# SiFive_FE200 register map
File version: 0.1
From SiFive,FE200,model device generator
Registers are 8-bit, read-write, no defined reset value unless marked. A register's access mark holds for its fields unless they carry their own. Offsets are from the block's base; lines under a group give offsets from that group; [hi:lo] are bit positions; {n}, {i} and the like mark numbered series; 'fields as' and 'values as' point back to an identical list; <NAME> marks a mode.

## Memory map
0x00004000 sifive_test0_0 size 0x1000 — From sifive,test0,control peripheral generator
0x02000000 sifive_clic0_0 size 0x1000000 — From sifive,clic0,control peripheral generator
0x20000000 sifive_uart0_0 size 0x1000 — From sifive,uart0,control peripheral generator
0x20002000 sifive_gpio0_0 size 0x1000 — From sifive,gpio0,control peripheral generator
0x20004000 sifive_spi0_0 size 0x1000 — From sifive,spi0,control peripheral generator
0x20005000 sifive_pwm0_0 size 0x1000 — From sifive,pwm0,control peripheral generator

## sifive_gpio0_0 — From sifive,gpio0,control peripheral generator
Base 0x20002000
0x00 input_val 32-bit — Pin value
0x04 input_en 32-bit — Pin input enable
0x08 output_en 32-bit — Pin output enable
0x0C output_val 32-bit — Output value
0x10 pue 32-bit — Internal pull-up enable
0x14 ds 32-bit — Pin drive strength
0x18 rise_ie 32-bit — Rise interrupt enable
0x1C rise_ip 32-bit — Rise interrupt pending
0x20 fall_ie 32-bit — Fall interrupt enable
0x24 fall_ip 32-bit — Fall interrupt pending
0x28 high_ie 32-bit — High interrupt enable
0x2C high_ip 32-bit — High interrupt pending
0x30 low_ie 32-bit — Low interrupt enable
0x34 low_ip 32-bit — Low interrupt pending
0x38 iof_en 32-bit — I/O function enable
0x3C iof_sel 32-bit — I/O function select
0x40 out_xor 32-bit — Output XOR (invert)

## sifive_clic0_0 — From sifive,clic0,control peripheral generator
Base 0x02000000
0x00 msip_0 32-bit — MSIP Register for hart 0
0x4000 mtimecmp_0 64-bit — MTIMECMP Register for hart 0
0xBFF8 mtime 64-bit
{0x800000+i} clicintip_{i} (i=0..172) — CLICINTIP Register for interrupt id {i}
{0x800400+i} clicintie_{i} (i=0..172) — CLICINTIE Register for interrupt id {i}
{0x800800+i} clicintctl_{i} (i=0..172) — CLICINTCTL Register for interrupt id {i}
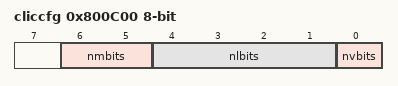
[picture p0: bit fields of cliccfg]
0x800C00 cliccfg
  [6:5] nmbits ro — Determines the number of Mode bits available in clicintctl.
  [4:1] nlbits — Determines the number of Level bits available in clicintctl.
  [0] nvbits — When set, selective hardware vectoring is enabled.

## sifive_pwm0_0 — From sifive,pwm0,control peripheral generator
Base 0x20005000
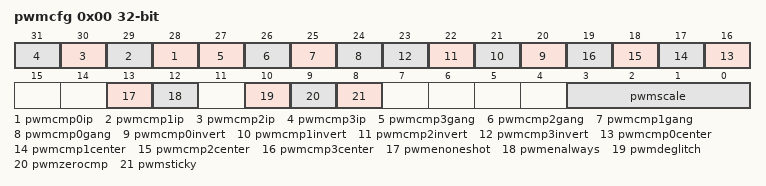
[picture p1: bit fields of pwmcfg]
0x00 pwmcfg 32-bit — PWM configuration register
  [n+28] pwmcmp{n}ip (n=0..3) — PWM{n} Interrupt Pending
  [27] pwmcmp3gang — PWM3/PWM0 Compare Gang
  [26] pwmcmp2gang — PWM2/PWM3 Compare Gang
  [25] pwmcmp1gang — PWM1/PWM2 Compare Gang
  [24] pwmcmp0gang — PWM0/PWM1 Compare Gang
  [n+20] pwmcmp{n}invert (n=0..3) — PWM{n} Invert
  [n+16] pwmcmp{n}center (n=0..3) — PWM{n} Compare Center
  [13] pwmenoneshot — PWM enable one shot - run one cycle
  [12] pwmenalways — PWM enable always - run continuously
  [10] pwmdeglitch — PWM Deglitch - latch pwmcmpXip within same cycle
  [9] pwmzerocmp — PWM Zero - counter resets to zero after match
  [8] pwmsticky — PWM Sticky - disallow clearing pwmcmpXip bits
  [3:0] pwmscale — PWM Counter scale
0x08 pwmcount 32-bit
  [30:0] pwmcount
0x10 pwms 32-bit — Scaled PWM count register
  [15:0] pwms — Scaled PWM count register.
{0x20+4i} pwmcmp{i} 32-bit (i=0..3) — PWM {i} compare register
  [15:0] pwmcmp{i} — PWM {i} Compare Value

## sifive_uart0_0 — From sifive,uart0,control peripheral generator
Base 0x20000000
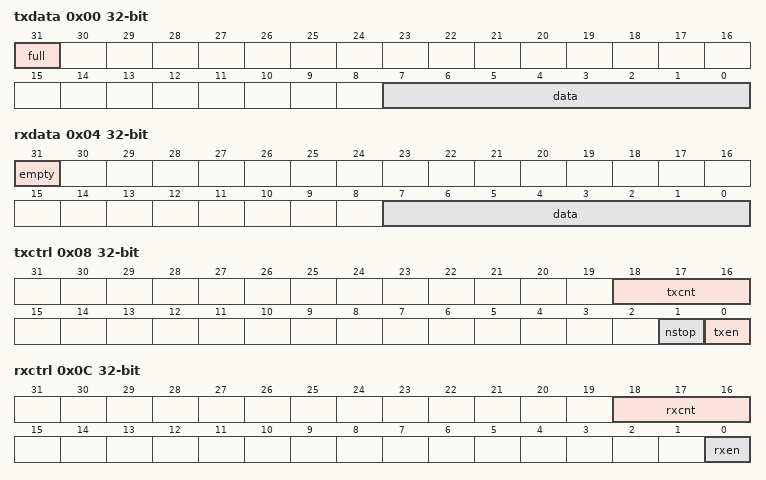
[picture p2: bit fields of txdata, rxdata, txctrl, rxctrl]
0x00 txdata 32-bit — Transmit data register
  [31] full ro — Transmit FIFO full
  [7:0] data — Transmit data
0x04 rxdata 32-bit — Receive data register
  [31] empty ro — Receive FIFO empty
  [7:0] data ro — Received data
0x08 txctrl 32-bit — Transmit control register
  [18:16] txcnt — Transmit watermark level
  [1] nstop — Number of stop bits
  [0] txen — Transmit enable
0x0C rxctrl 32-bit — Receive control register
  [18:16] rxcnt — Receive watermark level
  [0] rxen — Receive enable
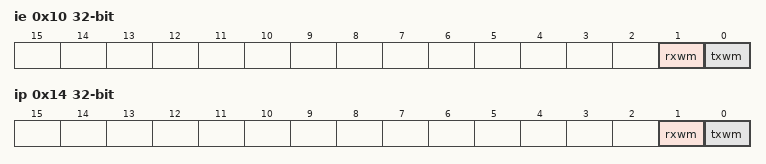
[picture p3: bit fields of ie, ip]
0x10 ie 32-bit — UART interrupt enable
  [1] rxwm — Receive watermark interrupt enable
  [0] txwm — Transmit watermark interrupt enable
0x14 ip 32-bit — UART interrupt pending
  [1] rxwm ro — Receive watermark interrupt pending
  [0] txwm ro — Transmit watermark interrupt pending
0x18 div 32-bit — Baud rate divisor
  [15:0] div — Baud rate divisor.

## sifive_spi0_0 — From sifive,spi0,control peripheral generator
Base 0x20004000
0x00 sckdiv 32-bit — Serial clock divisor
  [11:0] div — Divisor for serial clock.
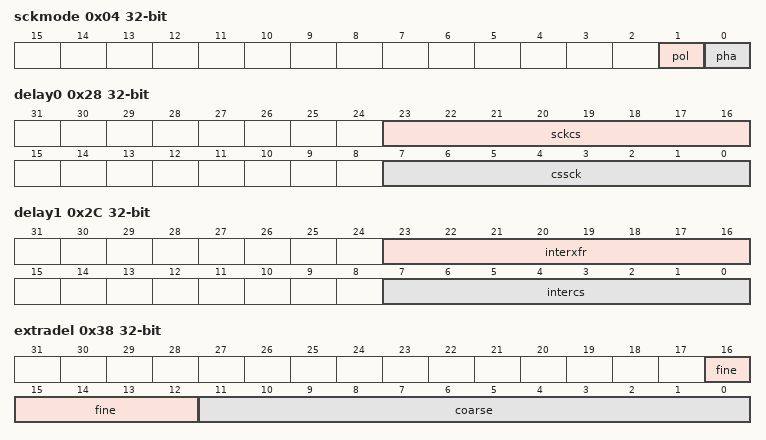
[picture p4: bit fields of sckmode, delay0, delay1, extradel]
0x04 sckmode 32-bit — Serial clock mode
  [1] pol — Serial clock polarity
  [0] pha — Serial clock phase
0x10 csid 32-bit — Chip select ID
  [31:0] csid — Chip select ID.
0x14 csdef 32-bit — Chip select default
  [31:0] csdef — Chip select default value. Reset to all-1s.
0x18 csmode 32-bit — Chip select mode
  [1:0] mode
0x28 delay0 32-bit — Delay control 0
  [23:16] sckcs — SCK to CS Delay
  [7:0] cssck — CS to SCK Delay
0x2C delay1 32-bit — Delay control 1
  [23:16] interxfr — Maximum interframe delay
  [7:0] intercs — Minimum CS inactive time
0x38 extradel 32-bit — SPI extra sampling delay to increase the SPI frequency
  [16:12] fine — Fine grain sample delay (multiples of process-specific buffer delay)
  [11:0] coarse — Coarse grain sample delay (multiples of system clocks)
0x3C sampledel 32-bit — Number of delay stages from slave to the SPI controller
  [4:0] sd — Number of delay stages from slave to SPI controller
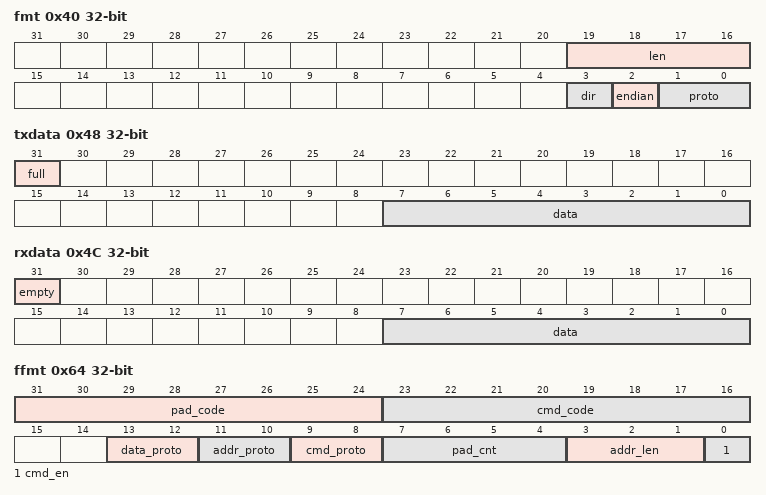
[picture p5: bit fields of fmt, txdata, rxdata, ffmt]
0x40 fmt 32-bit — Frame format
  [19:16] len — Number of bits per frame
  [3] dir — SPI I/O direction. This is reset to 1 for flash-enabled SPI controllers, 0 otherwise.
  [2] endian — SPI endianness
  [1:0] proto — SPI protocol
0x48 txdata 32-bit — Tx FIFO Data
  [31] full ro — FIFO full flag
  [7:0] data — Transmit data
0x4C rxdata 32-bit — Rx FIFO data
  [31] empty — FIFO empty flag
  [7:0] data ro — Received data
0x50 txmark 32-bit — Tx FIFO watermark
  [2:0] txmark — Transmit watermark. The reset value is 1 for flash-enabled controllers, 0 otherwise.
0x54 rxmark 32-bit — Rx FIFO watermark
  [2:0] rxmark — Receive watermark
0x60 fctrl 32-bit — SPI flash interface control
  [0] en — SPI Flash Mode Select
0x64 ffmt 32-bit — SPI flash instruction format
  [31:24] pad_code — First 8 bits to transmit during dummy cycles
  [23:16] cmd_code — Value of command byte
  [13:12] data_proto — Protocol for receiving data bytes
  [11:10] addr_proto — Protocol for transmitting address and padding
  [9:8] cmd_proto — Protocol for transmitting command
  [7:4] pad_cnt — Number of dummy cycles
  [3:1] addr_len — Number of address bytes (0 to 4)
  [0] cmd_en — Enable sending of command
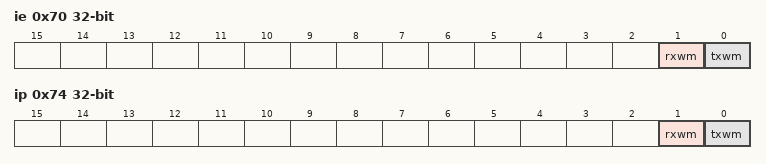
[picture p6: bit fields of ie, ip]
0x70 ie 32-bit — SPI interrupt enable
  [1] rxwm — Receive watermark enable
  [0] txwm — Transmit watermark enable
0x74 ip 32-bit — SPI interrupt pending
  [1] rxwm ro — Receive watermark pending
  [0] txwm ro — Transmit watermark pending

## sifive_test0_0 — From sifive,test0,control peripheral generator
Base 0x00004000
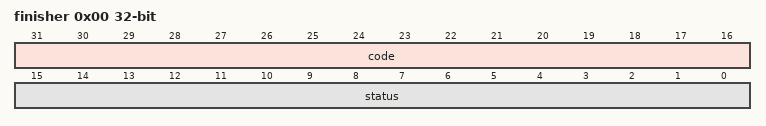
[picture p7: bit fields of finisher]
0x00 finisher 32-bit — Test finisher register
  [31:16] code — Finisher code
  [15:0] status — Test status
